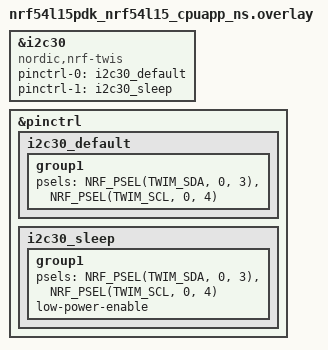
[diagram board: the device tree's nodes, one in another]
twi_slave: &i2c30 {
	compatible = "nordic,nrf-twis";
	status = "okay";
	pinctrl-0 = <&i2c30_default>;
	pinctrl-1 = <&i2c30_sleep>;
	pinctrl-names = "default", "sleep";
};

&pinctrl {
	i2c30_default: i2c30_default {
		group1 {
			psels = <NRF_PSEL(TWIM_SDA, 0, 3)>,
				<NRF_PSEL(TWIM_SCL, 0, 4)>;
		};
	};
	i2c30_sleep: i2c30_sleep {
		group1 {
			psels = <NRF_PSEL(TWIM_SDA, 0, 3)>,
				<NRF_PSEL(TWIM_SCL, 0, 4)>;
			low-power-enable;
		};
	};
};

